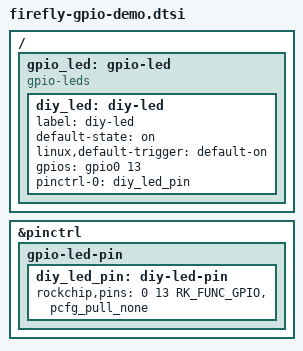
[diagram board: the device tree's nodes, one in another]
/*
 * (C) Copyright 2022 FireflyTeam <service@t-firefly.com>
 *
 * SPDX-License-Identifier:	GPL-2.0+
 */

/ {
	gpio_led: gpio-led {
		compatible = "gpio-leds";

		diy_led: diy-led {
			label = "diy-led";
			default-state = "on";
			linux,default-trigger = "default-on";
//			linux,default-trigger = "timer";
			gpios = <&gpio0 13 GPIO_ACTIVE_HIGH>;
			pinctrl-names = "default";
			pinctrl-0 = <&diy_led_pin>;
		};
	};
};

&pinctrl {
	gpio-led-pin {
		diy_led_pin: diy-led-pin {
			rockchip,pins =
			    <0 13 RK_FUNC_GPIO &pcfg_pull_none>;
		};
	};
};

